# STM32WB06 register map
File version: 1.0
CPU: CM0+ r0p0, little endian, MPU, no FPU, 2 interrupt priority bits
Registers are 32-bit, read-write, reset 0x0 unless marked. A register's access mark holds for its fields unless they carry their own. Offsets are from the block's base; [hi:lo] are bit positions; {n}, {i} and the like mark numbered series.

## DMAMUX
Base 0x48800000
{0x0+4i} C{i}CR (i=0..7) (reset mask 0xF) — CxCR register
  [4:0] DMAREQ_ID — DMAREQ_ID[4:0]: DMA REQuest IDentification Selects the input DMA request. C.f. the DMAMUX table about assignments of multiplexer inputs to resources.
    2=Spi3Rx; 3=Spi3Tx; 4=Spi1Rx; 5=Spi1Tx; 6=Spi2Rx; 7=Spi2Tx; 8=I2c1Rx; 9=I2c1Tx; 10=I2c2Rx; 11=I2c2Tx; 12=UsartRx; 13=UsartTx; 14=LpuartRx; 15=LpuartTx; 16=ADC_CH0 (DS channel); 17=ADC_CH1 (DF channel)

## GPIOA — GPIOA address block description
Base 0x48000000
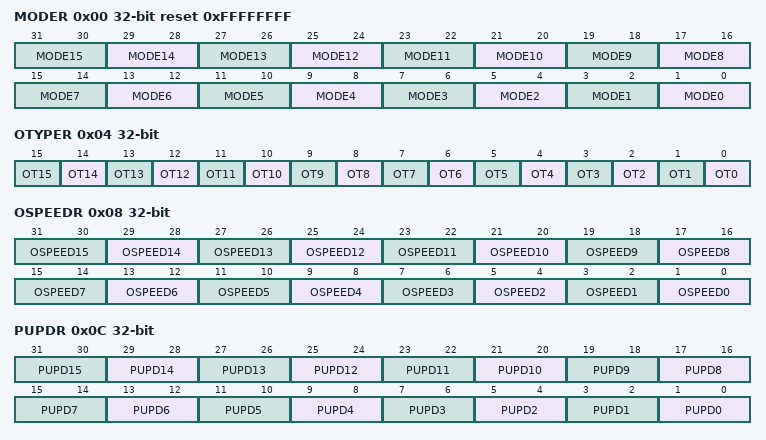
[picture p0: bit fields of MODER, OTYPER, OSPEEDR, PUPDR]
0x00 MODER reset 0xFFFFFFFF — GPIO port mode register
  [2n+1:2n] MODE{n} (n=0..15) — Port x configuration pin {n}
    0=Input mode; 1=Output (General purpose output mode); 2=Alternate function mode; 3=Analog mode
0x04 OTYPER — GPIO port output type register
  [n] OT{n} (n=0..15) — Port x configuration pin {n}
    0=PushPull (Output push-pull (reset state)); 1=OpenDrain (Output open-drain)
0x08 OSPEEDR — GPIO port output speed register
  [2n+1:2n] OSPEED{n} (n=0..15) — Port x configuration pin {n}
    0=LowSpeed; 1=MediumSpeed; 2=HighSpeed; 3=VeryHighSpeed
0x0C PUPDR — GPIO port pull-up/pull-down register
  [2n+1:2n] PUPD{n} (n=0..15) — Port x configuration pin {n}
    0=Floating (No pull-up, pull-down); 1=PullUp; 2=PullDown
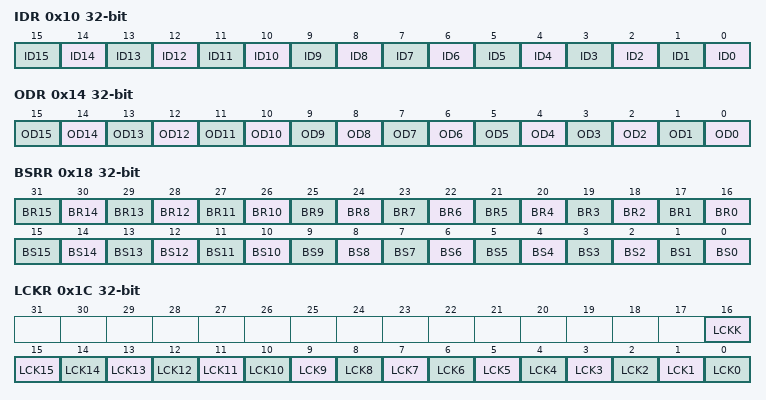
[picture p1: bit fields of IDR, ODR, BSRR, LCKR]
0x10 IDR ro (reset mask 0xFFFF0000) — GPIO port input data register
  [n] ID{n} (n=0..15) — Port input data pin {n}
    0=Low (Input is logic low); 1=High (Input is logic high)
0x14 ODR — GPIO port output data register
  [n] OD{n} (n=0..15) — Port output data pin {n}
    0=Low (Set output to logic low); 1=High (Set output to logic high)
0x18 BSRR wo — GPIO port bit set/reset register
  [n+16] BR{n} (n=0..15) — Port x reset pin {n}
    1=Resets the corresponding ODx bit
  [n] BS{n} (n=0..15) — Port x set pin {n}
    1=Set (Sets the corresponding ODx bit)
0x1C LCKR — GPIO port configuration lock register
  [16] LCKK — Lock key This bit can be read any time. It can only be modified using the lock key write sequence. LOCK key write sequence: WR LCKR[16] = '1' + LCKR[15:0] WR LCKR[16] = '0' + LCKR[15:0] WR LCKR[16] = '1' + LCKR[15:0] RD LCKR RD LCKR[16] = '1' (this read operation is optional but it confirms that the lock is active) Note: During the LOCK key write sequence, the value of LCK[15:0] must not change. Note: Any error in the lock sequence aborts the lock. Note: After the first lock sequence on any bit of the port, any read access on the LCKK bit returns '1' until the next MCU reset or peripheral reset.
    0=NotActive (Port configuration lock key not active); 1=Active (Port configuration lock key active)
  [n] LCK{n} (n=0..15) — Port x lock pin {n}
    0=Unlocked (Port configuration not locked); 1=Locked (Port configuration locked)
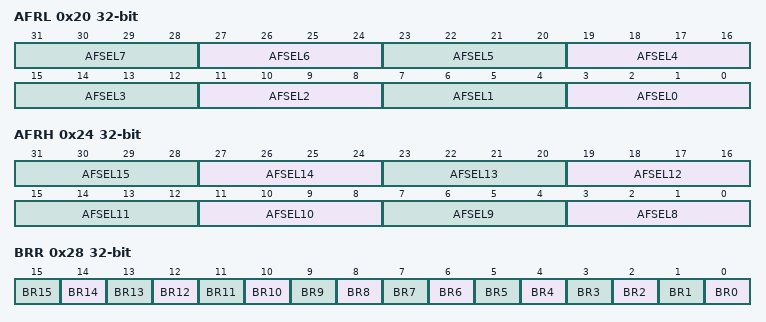
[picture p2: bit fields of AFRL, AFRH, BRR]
0x20 AFRL — GPIO alternate function low register
  [4n+3:4n] AFSEL{n} (n=0..7) — Alternate function selection for port x I/O pin y These bits are written by software to configure alternate function I/Os.
    {v}=AF{v} (v=0..15)
0x24 AFRH — GPIO alternate function high register
  [4n-29:4n-32] AFSEL{n} (n=8..15) — Alternate function selection for port x I/O pin y These bits are written by software to configure alternate function I/Os.
    {v}=AF{v} (v=0..15)
0x28 BRR wo — GPIO port bit reset register
  [n] BR{n} (n=0..15) — Port x reset pin {n}
    0=No action on the corresponding ODx bit; 1=Reset the ODx bit

## GLOBALSTATMACH
Base 0x200000C0
0x00 WORD0
  [31:0] RadioConfigPtr — Radio Configuration address Pointer.
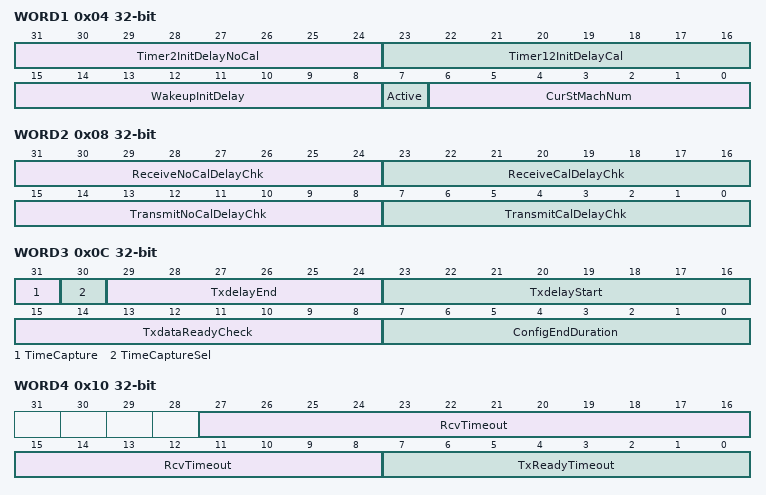
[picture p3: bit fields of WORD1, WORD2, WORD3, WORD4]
0x04 WORD1
  [31:24] Timer2InitDelayNoCal — Delay between Timer2 trig event on Sequencer and RX/TX request sending to the Radio FSM.
  [23:16] Timer12InitDelayCal — Delay between Timer1 or Timer2 trig event on Sequencer and RX/TX request sending to the Radio FSM.
  [15:8] WakeupInitDelay — Delay between wakeup timer trig event on Sequencer and RX/TX request sending to the Radio FSM.
  [7] Active — Must be at '1' when the trig event (Wakeup Timer, Timer1 or Timer2) occurs to starts a Bluetooth LE link layer sequence.
  [6:0] CurStMachNum — current connection machine number.
0x08 WORD2
  [31:24] ReceiveNoCalDelayChk — Delay between RX request sent to the Radio FSM and the start pulse to the receive block.
  [23:16] ReceiveCalDelayChk — Delay between RX request sent to the Radio FSM and the start pulse sent to the receive block.
  [15:8] TransmitNoCalDelayChk — Delay between TX request sent to the Radio FSM and the start pulse to the transmit block.
  [7:0] TransmitCalDelayChk — Delay between TX request sent to the Radio FSM and the start pulse sent to the transmit block.
0x0C WORD3
  [31] TimeCapture — - 0: No capture is requested to monitor the Bluetooth LE sequence.
  [30] TimeCaptureSel — - 0: the captured time (absolute time) corresponds to the end of 1st INIT step in the sequence (InitDelay timeout event).
  [29:24] TxdelayEnd — Delay added between the last bit transmission to the modulator and the end of transmission information for the Sequencer.
  [23:16] TxdelayStart — Delay added between the moment the Radio FSM is in TX mode (PA ramp up done and power present on the antenna) and the first bit transmission to the modulator.
  [15:8] TxdataReadyCheck — Duration for the Sequencer to get the TxDataReady and DataPtr information in TxRxPack table.
  [7:0] ConfigEndDuration — Duration for the Sequencer to execute the final configuration.
0x10 WORD4
  [27:8] RcvTimeout — Receive window timeout.
  [7:0] TxReadyTimeout — Transmission ready timeout.
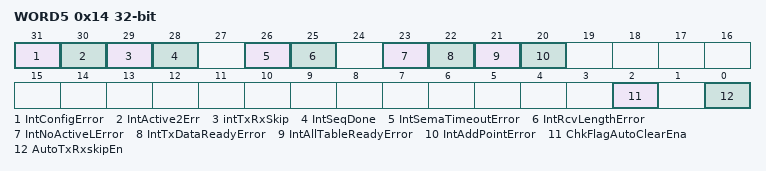
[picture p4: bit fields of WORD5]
0x14 WORD5
  [31] IntConfigError — Configuration error interrupt enable.
  [30] IntActive2Err — not in ACTIVE2 information from Radio FSM received on time interrupt enable.
  [29] intTxRxSkip — Transmission or reception skip interrupt enable.
  [28] IntSeqDone — Sequencer end of task interrupt enable.
  [26] IntSemaTimeoutError — Semaphore timeout error interrupt enable.
  [25] IntRcvLengthError — Too long received payload length interrupt enable.
  [23] IntNoActiveLError — Active bit low value reading interrupt enable.
  [22] IntTxDataReadyError — Transmission data payload ready error interrupt enable.
  [21] IntAllTableReadyError — All table ready error interrupt enable.
  [20] IntAddPointError — Address pointer error interrupt enable.
  [2] ChkFlagAutoClearEna — Active bit Auto Clear Enable.
  [0] AutoTxRxskipEn — Automatic transfer (TX or RX) skip enable.
0x18 WORD6
  [6:0] DefaultAntennaID — Default Antenna ID corresponding to the number of the antenna used to receive/transmit:
